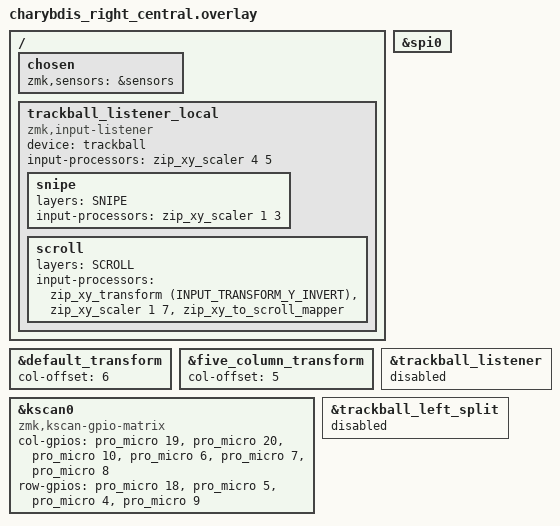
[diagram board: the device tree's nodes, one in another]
#include "charybdis.dtsi"
#include "charybdis_3610.dtsi"
#include "charybdis_ec11.dtsi"
#include "split_input.dtsi"

/ {
	chosen {
		zmk,sensors = &sensors;
	};

	trackball_listener_local: trackball_listener_local {
		compatible = "zmk,input-listener";
		device = <&trackball>;

		input-processors = <&zip_xy_scaler 4 5>;

		snipe {
			layers = <SNIPE>;
			input-processors = <&zip_xy_scaler 1 3>;
		};

		scroll {
			layers = <SCROLL>;
			input-processors = <&zip_xy_transform (INPUT_TRANSFORM_Y_INVERT)>, <&zip_xy_scaler 1 7>, <&zip_xy_to_scroll_mapper>;
		};
	};
};

&default_transform {
	col-offset = <6>;
};

&five_column_transform {
	col-offset = <5>;
};

&kscan0 {
	compatible = "zmk,kscan-gpio-matrix";

	col-gpios
		= <&pro_micro 19 (GPIO_ACTIVE_HIGH | GPIO_PULL_DOWN)>
		, <&pro_micro 20 (GPIO_ACTIVE_HIGH | GPIO_PULL_DOWN)>
		, <&pro_micro 10 (GPIO_ACTIVE_HIGH | GPIO_PULL_DOWN)>
		, <&pro_micro 6 (GPIO_ACTIVE_HIGH | GPIO_PULL_DOWN)>
		, <&pro_micro 7 (GPIO_ACTIVE_HIGH | GPIO_PULL_DOWN)>
		, <&pro_micro 8 (GPIO_ACTIVE_HIGH | GPIO_PULL_DOWN)>
		;

	row-gpios
		= <&pro_micro 18 GPIO_ACTIVE_HIGH>
		, <&pro_micro 5 GPIO_ACTIVE_HIGH>
		, <&pro_micro 4 GPIO_ACTIVE_HIGH>
		, <&pro_micro 9 GPIO_ACTIVE_HIGH>
		;
};

&spi0 {
    status = "okay";
};

&trackball_listener {
    status = "disabled";
};

&trackball_left_split {
    status = "disabled";
};
